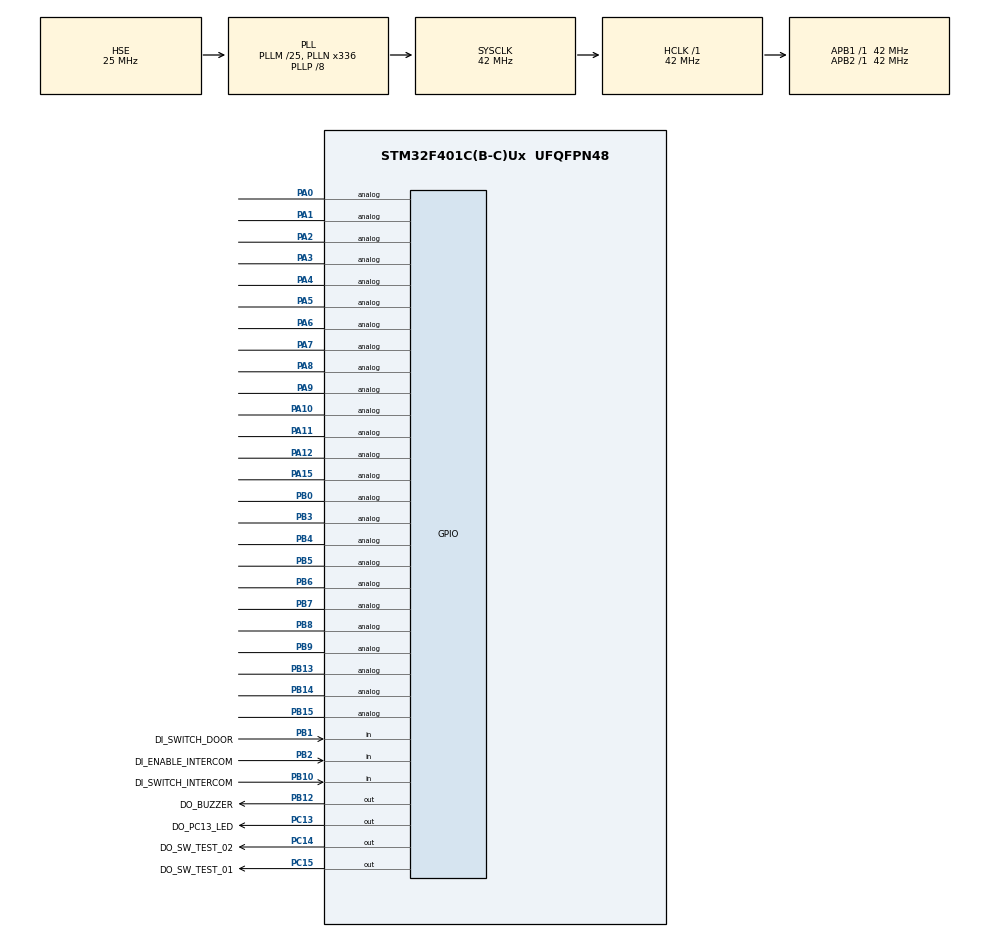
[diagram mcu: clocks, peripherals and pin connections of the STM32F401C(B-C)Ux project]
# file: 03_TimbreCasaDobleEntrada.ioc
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IWDG.Prescaler=IWDG_PRESCALER_128
IWDG.Reload=749
Mcu.Family=STM32F4
Mcu.Name=STM32F401C(B-C)Ux
Mcu.Package=UFQFPN48
NVIC.PriorityGroup=NVIC_PRIORITYGROUP_4
PA0-WKUP.Signal=GPIO_Analog
PA1.Signal=GPIO_Analog
PA10.Signal=GPIO_Analog
PA11.Signal=GPIO_Analog
PA12.Signal=GPIO_Analog
PA13.Mode=Serial_Wire
PA13.Signal=SYS_JTMS-SWDIO
PA14.Mode=Serial_Wire
PA14.Signal=SYS_JTCK-SWCLK
PA15.Signal=GPIO_Analog
PA2.Signal=GPIO_Analog
PA3.Signal=GPIO_Analog
PA4.Signal=GPIO_Analog
PA5.Signal=GPIO_Analog
PA6.Signal=GPIO_Analog
PA7.Signal=GPIO_Analog
PA8.Signal=GPIO_Analog
PA9.Signal=GPIO_Analog
PB0.Signal=GPIO_Analog
PB1.GPIO_Label=DI_SWITCH_DOOR
PB1.GPIO_PuPd=GPIO_PULLUP
PB1.Signal=GPIO_Input
PB10.GPIO_Label=DI_SWITCH_INTERCOM
PB10.GPIO_PuPd=GPIO_PULLUP
PB10.Signal=GPIO_Input
PB12.GPIO_Label=DO_BUZZER
PB12.GPIO_PuPd=GPIO_PULLDOWN
PB12.Signal=GPIO_Output
PB13.Signal=GPIO_Analog
PB14.Signal=GPIO_Analog
PB15.Signal=GPIO_Analog
PB2.GPIO_Label=DI_ENABLE_INTERCOM
PB2.GPIO_PuPd=GPIO_PULLUP
PB2.Signal=GPIO_Input
PB3.Signal=GPIO_Analog
PB4.Signal=GPIO_Analog
PB5.Signal=GPIO_Analog
PB6.Signal=GPIO_Analog
PB7.Signal=GPIO_Analog
PB8.Signal=GPIO_Analog
PB9.Signal=GPIO_Analog
PC13-ANTI_TAMP.GPIO_Label=DO_PC13_LED
PC13-ANTI_TAMP.Signal=GPIO_Output
PC14-OSC32_IN.GPIO_Label=DO_SW_TEST_02
PC14-OSC32_IN.GPIO_PuPd=GPIO_PULLDOWN
PC14-OSC32_IN.Signal=GPIO_Output
PC15-OSC32_OUT.GPIO_Label=DO_SW_TEST_01
PC15-OSC32_OUT.GPIO_PuPd=GPIO_PULLDOWN
PC15-OSC32_OUT.Signal=GPIO_Output
PH0\ -\ OSC_IN.Mode=HSE-External-Oscillator
PH0\ -\ OSC_IN.Signal=RCC_OSC_IN
PH1\ -\ OSC_OUT.Mode=HSE-External-Oscillator
PH1\ -\ OSC_OUT.Signal=RCC_OSC_OUT
ProjectManager.HeapSize=0x200
ProjectManager.StackSize=0x400
ProjectManager.TargetToolchain=STM32CubeIDE
RCC.48MHZClocksFreq_Value=168000000
RCC.AHBFreq_Value=42000000
RCC.APB1Freq_Value=42000000
RCC.APB1TimFreq_Value=42000000
RCC.APB2Freq_Value=42000000
RCC.APB2TimFreq_Value=42000000
RCC.CortexFreq_Value=42000000
RCC.EnbaleCSS=true
RCC.HCLKFreq_Value=42000000
RCC.HSE_VALUE=25000000
RCC.HSI_VALUE=16000000
RCC.LSE_VALUE=32768
RCC.PLLI2SN=50
RCC.PLLM=25
RCC.PLLN=336
RCC.PLLP=RCC_PLLP_DIV8
RCC.PLLQ=2
RCC.PLLSourceVirtual=RCC_PLLSOURCE_HSE
RCC.SYSCLKFreq_VALUE=42000000
RCC.SYSCLKSource=RCC_SYSCLKSOURCE_PLLCLK
RCC.VCOOutputFreq_Value=336000000
VP_IWDG_VS_IWDG.Mode=IWDG_Activate
board=custom

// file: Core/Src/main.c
/* USER CODE BEGIN Header */
/**
  ******************************************************************************
  * @file           : main.c
  * @brief          : Main program body
  ******************************************************************************
  * @attention
  *
  * Copyright (c) 2025 STMicroelectronics.
  * All rights reserved.
  *
  * This software is licensed under terms that can be found in the LICENSE file
  * in the root directory of this software component.
  * If no LICENSE file comes with this software, it is provided AS-IS.
  *
  ******************************************************************************
  */
/* USER CODE END Header */
#include "main.h"

/* USER CODE BEGIN Includes */
#include "libTypes_api.h"
#include "osd_api.h"
/* USER CODE END Includes */

IWDG_HandleTypeDef hiwdg;

void SystemClock_Config(void);
static void MX_GPIO_Init(void);
static void MX_IWDG_Init(void);

int main(void)
{

  /* MCU Configuration--------------------------------------------------------*/

  /* Reset of all peripherals, Initializes the Flash interface and the Systick. */
  HAL_Init();

  /* Configure the system clock */
  SystemClock_Config();

  /* USER CODE BEGIN SysInit */
  OSD_Init();
  /* USER CODE END SysInit */

  /* Initialize all configured peripherals */
  MX_GPIO_Init();
  MX_IWDG_Init();

  /* Infinite loop */
  /* USER CODE BEGIN WHILE */
  while (1)
  {
    // Code executed at ISR SysTick_Handler
    /* USER CODE END WHILE */

  }
}

void SystemClock_Config(void)
{
  RCC_OscInitTypeDef RCC_OscInitStruct = {0};
  RCC_ClkInitTypeDef RCC_ClkInitStruct = {0};

  /** Configure the main internal regulator output voltage
  */
  __HAL_RCC_PWR_CLK_ENABLE();
  __HAL_PWR_VOLTAGESCALING_CONFIG(PWR_REGULATOR_VOLTAGE_SCALE2);

  /** Initializes the RCC Oscillators according to the specified parameters
  * in the RCC_OscInitTypeDef structure.
  */
  RCC_OscInitStruct.OscillatorType = RCC_OSCILLATORTYPE_LSI|RCC_OSCILLATORTYPE_HSE;
  RCC_OscInitStruct.HSEState = RCC_HSE_ON;
  RCC_OscInitStruct.LSIState = RCC_LSI_ON;
  RCC_OscInitStruct.PLL.PLLState = RCC_PLL_ON;
  RCC_OscInitStruct.PLL.PLLSource = RCC_PLLSOURCE_HSE;
  RCC_OscInitStruct.PLL.PLLM = 25;
  RCC_OscInitStruct.PLL.PLLN = 336;
  RCC_OscInitStruct.PLL.PLLP = RCC_PLLP_DIV8;
  RCC_OscInitStruct.PLL.PLLQ = 2;
  if (HAL_RCC_OscConfig(&RCC_OscInitStruct) != HAL_OK)
  {
    Error_Handler();
  }

  /** Initializes the CPU, AHB and APB buses clocks
  */
  RCC_ClkInitStruct.ClockType = RCC_CLOCKTYPE_HCLK|RCC_CLOCKTYPE_SYSCLK
                              |RCC_CLOCKTYPE_PCLK1|RCC_CLOCKTYPE_PCLK2;
  RCC_ClkInitStruct.SYSCLKSource = RCC_SYSCLKSOURCE_PLLCLK;
  RCC_ClkInitStruct.AHBCLKDivider = RCC_SYSCLK_DIV1;
  RCC_ClkInitStruct.APB1CLKDivider = RCC_HCLK_DIV1;
  RCC_ClkInitStruct.APB2CLKDivider = RCC_HCLK_DIV1;

  if (HAL_RCC_ClockConfig(&RCC_ClkInitStruct, FLASH_LATENCY_1) != HAL_OK)
  {
    Error_Handler();
  }

  /** Enables the Clock Security System
  */
  HAL_RCC_EnableCSS();
}

static void MX_IWDG_Init(void)
{

  hiwdg.Instance = IWDG;
  hiwdg.Init.Prescaler = IWDG_PRESCALER_128;
  hiwdg.Init.Reload = 749;
  if (HAL_IWDG_Init(&hiwdg) != HAL_OK)
  {
    Error_Handler();
  }

}

static void MX_GPIO_Init(void)
{
  GPIO_InitTypeDef GPIO_InitStruct = {0};

  /* GPIO Ports Clock Enable */
  __HAL_RCC_GPIOC_CLK_ENABLE();
  __HAL_RCC_GPIOH_CLK_ENABLE();
  __HAL_RCC_GPIOA_CLK_ENABLE();
  __HAL_RCC_GPIOB_CLK_ENABLE();

  /*Configure GPIO pin Output Level */
  HAL_GPIO_WritePin(GPIOC, DO_PC13_LED_Pin|DO_SW_TEST_02_Pin|DO_SW_TEST_01_Pin, GPIO_PIN_RESET);

  /*Configure GPIO pin Output Level */
  HAL_GPIO_WritePin(DO_BUZZER_GPIO_Port, DO_BUZZER_Pin, GPIO_PIN_RESET);

  /*Configure GPIO pin : DO_PC13_LED_Pin */
  GPIO_InitStruct.Pin = DO_PC13_LED_Pin;
  GPIO_InitStruct.Mode = GPIO_MODE_OUTPUT_PP;
  GPIO_InitStruct.Pull = GPIO_NOPULL;
  GPIO_InitStruct.Speed = GPIO_SPEED_FREQ_LOW;
  HAL_GPIO_Init(DO_PC13_LED_GPIO_Port, &GPIO_InitStruct);

  /*Configure GPIO pins : DO_SW_TEST_02_Pin DO_SW_TEST_01_Pin */
  GPIO_InitStruct.Pin = DO_SW_TEST_02_Pin|DO_SW_TEST_01_Pin;
  GPIO_InitStruct.Mode = GPIO_MODE_OUTPUT_PP;
  GPIO_InitStruct.Pull = GPIO_PULLDOWN;
  GPIO_InitStruct.Speed = GPIO_SPEED_FREQ_LOW;
  HAL_GPIO_Init(GPIOC, &GPIO_InitStruct);

  /*Configure GPIO pins : PA0 PA1 PA2 PA3
                           PA4 PA5 PA6 PA7
                           PA8 PA9 PA10 PA11
                           PA12 PA15 */
  GPIO_InitStruct.Pin = GPIO_PIN_0|GPIO_PIN_1|GPIO_PIN_2|GPIO_PIN_3
                          |GPIO_PIN_4|GPIO_PIN_5|GPIO_PIN_6|GPIO_PIN_7
                          |GPIO_PIN_8|GPIO_PIN_9|GPIO_PIN_10|GPIO_PIN_11
                          |GPIO_PIN_12|GPIO_PIN_15;
  GPIO_InitStruct.Mode = GPIO_MODE_ANALOG;
  GPIO_InitStruct.Pull = GPIO_NOPULL;
  HAL_GPIO_Init(GPIOA, &GPIO_InitStruct);

  /*Configure GPIO pins : PB0 PB13 PB14 PB15
                           PB3 PB4 PB5 PB6
                           PB7 PB8 PB9 */
  GPIO_InitStruct.Pin = GPIO_PIN_0|GPIO_PIN_13|GPIO_PIN_14|GPIO_PIN_15
                          |GPIO_PIN_3|GPIO_PIN_4|GPIO_PIN_5|GPIO_PIN_6
                          |GPIO_PIN_7|GPIO_PIN_8|GPIO_PIN_9;
  GPIO_InitStruct.Mode = GPIO_MODE_ANALOG;
  GPIO_InitStruct.Pull = GPIO_NOPULL;
  HAL_GPIO_Init(GPIOB, &GPIO_InitStruct);

  /*Configure GPIO pins : DI_SWITCH_DOOR_Pin DI_ENABLE_INTERCOM_Pin DI_SWITCH_INTERCOM_Pin */
  GPIO_InitStruct.Pin = DI_SWITCH_DOOR_Pin|DI_ENABLE_INTERCOM_Pin|DI_SWITCH_INTERCOM_Pin;
  GPIO_InitStruct.Mode = GPIO_MODE_INPUT;
  GPIO_InitStruct.Pull = GPIO_PULLUP;
  HAL_GPIO_Init(GPIOB, &GPIO_InitStruct);

  /*Configure GPIO pin : DO_BUZZER_Pin */
  GPIO_InitStruct.Pin = DO_BUZZER_Pin;
  GPIO_InitStruct.Mode = GPIO_MODE_OUTPUT_PP;
  GPIO_InitStruct.Pull = GPIO_PULLDOWN;
  GPIO_InitStruct.Speed = GPIO_SPEED_FREQ_LOW;
  HAL_GPIO_Init(DO_BUZZER_GPIO_Port, &GPIO_InitStruct);

}

void Error_Handler(void)
{
  __disable_irq();
  while (1)
  {
  }
}
